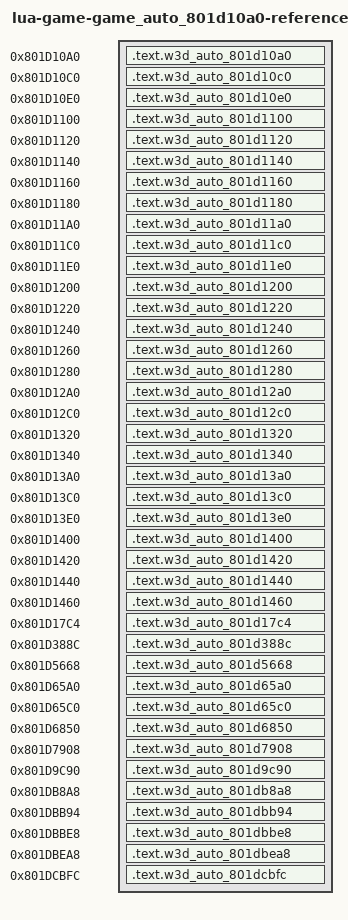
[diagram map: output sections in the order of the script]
/* Generated reference-only placements. All bodies are source-built. */
OUTPUT_FORMAT("elf32-powerpc")
OUTPUT_ARCH(powerpc)
ENTRY(w3d_auto_801d10a0)
_SDA_BASE_ = 0x804b2540;
_SDA2_BASE_ = 0x804c2540;
fn_801A381C = 0x801a381c;
fn_801A3944 = 0x801a3944;
fn_802134FC = 0x802134fc;
SECTIONS {
  .text.w3d_auto_801d10a0 0x801d10a0 : { *(.text.w3d_auto_801d10a0) }
  .text.w3d_auto_801d10c0 0x801d10c0 : { *(.text.w3d_auto_801d10c0) }
  .text.w3d_auto_801d10e0 0x801d10e0 : { *(.text.w3d_auto_801d10e0) }
  .text.w3d_auto_801d1100 0x801d1100 : { *(.text.w3d_auto_801d1100) }
  .text.w3d_auto_801d1120 0x801d1120 : { *(.text.w3d_auto_801d1120) }
  .text.w3d_auto_801d1140 0x801d1140 : { *(.text.w3d_auto_801d1140) }
  .text.w3d_auto_801d1160 0x801d1160 : { *(.text.w3d_auto_801d1160) }
  .text.w3d_auto_801d1180 0x801d1180 : { *(.text.w3d_auto_801d1180) }
  .text.w3d_auto_801d11a0 0x801d11a0 : { *(.text.w3d_auto_801d11a0) }
  .text.w3d_auto_801d11c0 0x801d11c0 : { *(.text.w3d_auto_801d11c0) }
  .text.w3d_auto_801d11e0 0x801d11e0 : { *(.text.w3d_auto_801d11e0) }
  .text.w3d_auto_801d1200 0x801d1200 : { *(.text.w3d_auto_801d1200) }
  .text.w3d_auto_801d1220 0x801d1220 : { *(.text.w3d_auto_801d1220) }
  .text.w3d_auto_801d1240 0x801d1240 : { *(.text.w3d_auto_801d1240) }
  .text.w3d_auto_801d1260 0x801d1260 : { *(.text.w3d_auto_801d1260) }
  .text.w3d_auto_801d1280 0x801d1280 : { *(.text.w3d_auto_801d1280) }
  .text.w3d_auto_801d12a0 0x801d12a0 : { *(.text.w3d_auto_801d12a0) }
  .text.w3d_auto_801d12c0 0x801d12c0 : { *(.text.w3d_auto_801d12c0) }
  .text.w3d_auto_801d1320 0x801d1320 : { *(.text.w3d_auto_801d1320) }
  .text.w3d_auto_801d1340 0x801d1340 : { *(.text.w3d_auto_801d1340) }
  .text.w3d_auto_801d13a0 0x801d13a0 : { *(.text.w3d_auto_801d13a0) }
  .text.w3d_auto_801d13c0 0x801d13c0 : { *(.text.w3d_auto_801d13c0) }
  .text.w3d_auto_801d13e0 0x801d13e0 : { *(.text.w3d_auto_801d13e0) }
  .text.w3d_auto_801d1400 0x801d1400 : { *(.text.w3d_auto_801d1400) }
  .text.w3d_auto_801d1420 0x801d1420 : { *(.text.w3d_auto_801d1420) }
  .text.w3d_auto_801d1440 0x801d1440 : { *(.text.w3d_auto_801d1440) }
  .text.w3d_auto_801d1460 0x801d1460 : { *(.text.w3d_auto_801d1460) }
  .text.w3d_auto_801d17c4 0x801d17c4 : { *(.text.w3d_auto_801d17c4) }
  .text.w3d_auto_801d388c 0x801d388c : { *(.text.w3d_auto_801d388c) }
  .text.w3d_auto_801d5668 0x801d5668 : { *(.text.w3d_auto_801d5668) }
  .text.w3d_auto_801d65a0 0x801d65a0 : { *(.text.w3d_auto_801d65a0) }
  .text.w3d_auto_801d65c0 0x801d65c0 : { *(.text.w3d_auto_801d65c0) }
  .text.w3d_auto_801d6850 0x801d6850 : { *(.text.w3d_auto_801d6850) }
  .text.w3d_auto_801d7908 0x801d7908 : { *(.text.w3d_auto_801d7908) }
  .text.w3d_auto_801d9c90 0x801d9c90 : { *(.text.w3d_auto_801d9c90) }
  .text.w3d_auto_801db8a8 0x801db8a8 : { *(.text.w3d_auto_801db8a8) }
  .text.w3d_auto_801dbb94 0x801dbb94 : { *(.text.w3d_auto_801dbb94) }
  .text.w3d_auto_801dbbe8 0x801dbbe8 : { *(.text.w3d_auto_801dbbe8) }
  .text.w3d_auto_801dbea8 0x801dbea8 : { *(.text.w3d_auto_801dbea8) }
  .text.w3d_auto_801dcbfc 0x801dcbfc : { *(.text.w3d_auto_801dcbfc) }
  /DISCARD/ : { *(.text*) *(.rodata*) *(.data*) *(.bss*) *(.sdata*) *(.sbss*) *(.comment) }
}
